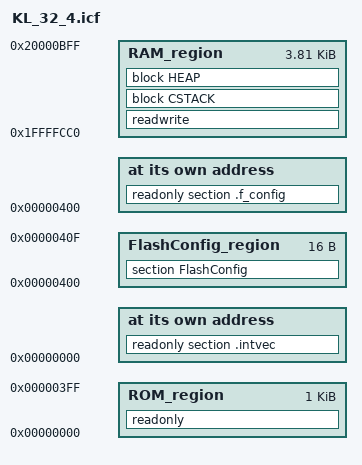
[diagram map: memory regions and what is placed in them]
/* KL_32_4.icf - for target in Flash          */
/* 32k Flash / 4k RAM                         */
define symbol __ICFEDIT_intvec_start__ = 0x00000000;
/*-Memory Regions-*/
define symbol __ICFEDIT_region_ROM_start__ = 0x00000000;
define symbol __ICFEDIT_region_ROM_end__   = 0x00007FFF;
define symbol __ICFEDIT_region_RAM_start__ = 0x1ffffcc0;
define symbol __ICFEDIT_region_RAM_end__   = 0x20000BFF;
/*-Sizes-*/
define symbol __ICFEDIT_size_cstack__ = 0x0;
define symbol __ICFEDIT_size_heap__   = 0x0;
/**** End of ICF editor section. ###ICF###*/

define symbol FlashConfig_start__= 0x00000400;
define symbol FlashConfig_end__  = 0x0000040f;

define memory mem with size = 4G;
define region ROM_region   = mem:[from __ICFEDIT_region_ROM_start__ to (FlashConfig_start__ - 1)] | [from (FlashConfig_end__+1)  to __ICFEDIT_region_ROM_end__];
define region RAM_region   = mem:[from __ICFEDIT_region_RAM_start__   to __ICFEDIT_region_RAM_end__];

define block CSTACK    with alignment = 8, size = __ICFEDIT_size_cstack__   { };
define block HEAP      with alignment = 8, size = __ICFEDIT_size_heap__     { };

define region FlashConfig_region = mem:[from FlashConfig_start__ to FlashConfig_end__];

initialize by copy { readwrite };
do not initialize  { section .noinit };

place at address mem:__ICFEDIT_intvec_start__ { readonly section .intvec };
place at address mem:FlashConfig_start__      { readonly section .f_config };

place in ROM_region   { readonly };
place in RAM_region   { readwrite,
                        block CSTACK, block HEAP };

place in FlashConfig_region
                      {section FlashConfig};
